# STM32WB5Mxx register map
File version: 1.0
Registers are 32-bit, read-write, reset 0x0 unless marked. A register's access mark holds for its fields unless they carry their own. Offsets are from the block's base; [hi:lo] are bit positions; {n}, {i} and the like mark numbered series.

## SYSCFG — System configuration controller
Base 0x40010000
0x00 MEMRMP — SYSCFG memory remap register
  [2:0] MEM_MODE — SYSCFG_Memory Remap Config
    0=FLASH (Main Flash memory mapped at 0x00000000); 1=SYSTEMFLASH (System Flash memory mapped at 0x00000000); 3=SRAM (SRAM1 mapped at 0x00000000); 6=QUADSPI (QUADSPI memory mapped at 0x00000000)
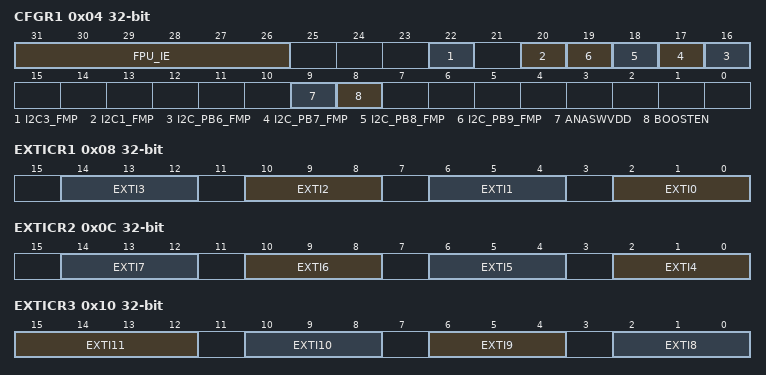
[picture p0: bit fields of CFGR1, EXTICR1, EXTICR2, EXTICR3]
0x04 CFGR1 — SYSCFG configuration register 1
  [31:26] FPU_IE — Cortex M4 Floating Point Unit interrupts enable bits
  [22] I2C3_FMP — I2C3 Fast-mode Plus (Fm+) driving capability activation
  [20] I2C1_FMP — I2C1 Fast-mode Plus (Fm+) driving capability activation
  [n+10] I2C_PB{n}_FMP (n=6..9) — Fast-mode Plus (Fm+) driving capability activation on PB{n}
  [9] ANASWVDD — I/O analog switch voltage selection
  [8] BOOSTEN — I/O analog switch voltage booster enable
0x08 EXTICR1 — SYSCFG external interrupt configuration registers
  [4n+2:4n] EXTI{n} (n=0..3) — External Interrupt Line {n} configuration
0x0C EXTICR2 — SYSCFG external interrupt configuration registers
  [4n-14:4n-16] EXTI{n} (n=4..7) — External Interrupt Line {n} configuration
0x10 EXTICR3 — SYSCFG external interrupt configuration registers
  [15:12] EXTI11 — External Interrupt Line 11 configuration
  [10:8] EXTI10 — External Interrupt Line 10 configuration
  [6:4] EXTI9 — External Interrupt Line 9 configuration
  [2:0] EXTI8 — External Interrupt Line 8 configuration
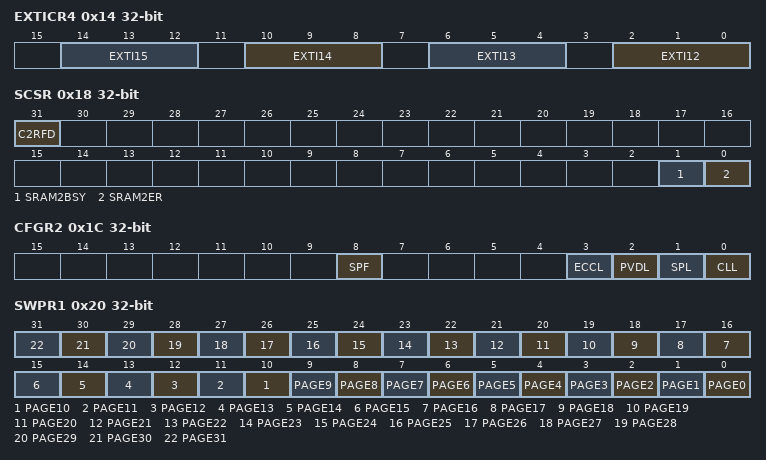
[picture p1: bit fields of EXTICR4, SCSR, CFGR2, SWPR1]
0x14 EXTICR4 — SYSCFG external interrupt configuration registers
  [4n-46:4n-48] EXTI{n} (n=12..15) — External Interrupt Line {n} configuration
0x18 SCSR — SYSCFG SRAM2 control and status register
  [31] C2RFD — CPU2 SRAM fetch (execution) disable
  [1] SRAM2BSY — SRAM2 and PKA RAM busy by erase operation
  [0] SRAM2ER — SRAM2 and PKA RAM Erase
0x1C CFGR2 — SYSCFG configuration register 2
  [8] SPF — SRAM2 Parity Lock
  [3] ECCL — ECC Lock
  [2] PVDL — PVD Lock
  [1] SPL — SRAM2 Parity Lock
  [0] CLL — Cortex M4 LOCKUP (hardfault) output enable
0x20 SWPR1 — SYSCFG SRAM2 write protection register part 1
  [n] PAGE{n} (n=0..31) — SRAM2A Write protection page {n} ({0x20030000+0x400*n} - {0x200303FF+0x400*n})
0x24 SKR — SYSCFG SRAM2 key register
  [7:0] KEY — SRAM2 write protection key for software erase
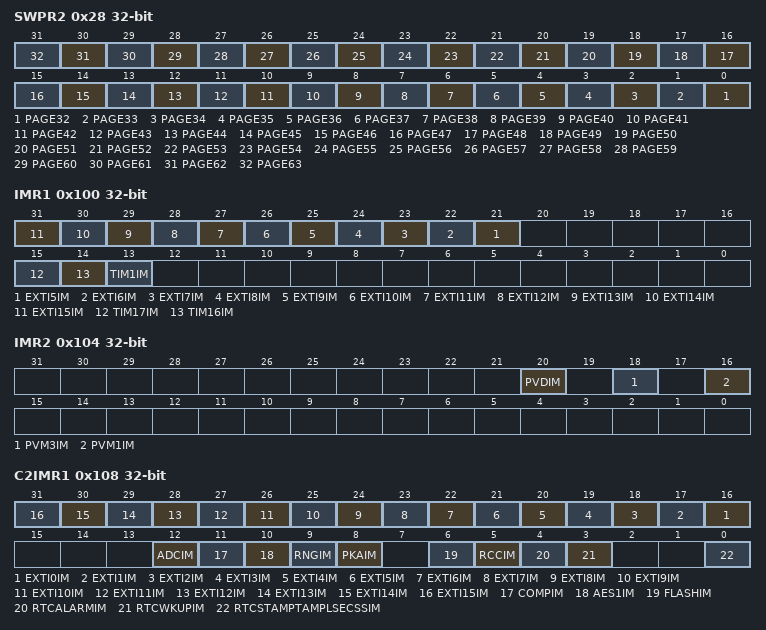
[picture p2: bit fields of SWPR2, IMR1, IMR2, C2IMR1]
0x28 SWPR2 — SYSCFG write protection register part 2
  [n-32] PAGE{n} (n=32..63) — SRAM2B Write protection page {n-32} ({0x20030000+0x400*n} - {0x200303FF+0x400*n})
0x100 IMR1 — SYSCFG CPU1 (CORTEX M4) interrupt masks control-status register part 1
  [n+16] EXTI{n}IM (n=5..15) — Enabling of interrupt from External Interrupt Line {n} to CPU1
  [15] TIM17IM — Enabling of interrupt from Timer 17 to CPU1
  [14] TIM16IM — Enabling of interrupt from Timer 16 to CPU1
  [13] TIM1IM — Enabling of interrupt from Timer 1 to CPU1
0x104 IMR2 — SYSCFG CPU1 (CORTEX M4) interrupt masks control-status register part 2
  [20] PVDIM — Enabling of interrupt from Power Voltage Detector to CPU1
  [18] PVM3IM — Enabling of interrupt from Power Voltage Monitoring 3 to CPU1
  [16] PVM1IM — Enabling of interrupt from Power Voltage Monitoring 1 to CPU1
0x108 C2IMR1 — SYSCFG CPU2 (CORTEX M0) interrupt masks control-status register part 1
  [n+16] EXTI{n}IM (n=0..15) — Enabling of interrupt from External Interrupt Line {n} to CPU2
  [12] ADCIM — Enabling of interrupt from Analog Digital Converter to CPU2
  [11] COMPIM — Enabling of interrupt from Comparator to CPU2
  [10] AES1IM — Enabling of interrupt from Advanced Encryption Standard 1 to CPU2
  [9] RNGIM — Enabling of interrupt from Random Number Generator to CPU2
  [8] PKAIM — Enabling of interrupt from Public Key Accelerator to CPU2
  [6] FLASHIM — Enabling of interrupt from FLASH to CPU2
  [5] RCCIM — Enabling of interrupt from RCC to CPU2
  [4] RTCALARMIM — Enabling of interrupt from RTC Alarms to CPU2
  [3] RTCWKUPIM — Enabling of interrupt from RTC Wakeup to CPU2
  [0] RTCSTAMPTAMPLSECSSIM
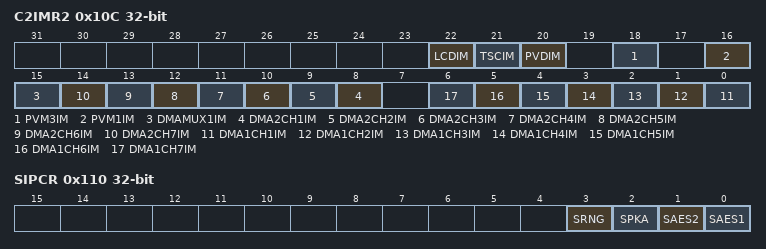
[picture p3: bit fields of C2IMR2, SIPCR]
0x10C C2IMR2 — SYSCFG CPU2 (CORTEX M0) interrupt masks control-status register part 2
  [22] LCDIM — Enabling of interrupt from Liquid Crystal Display to CPU2
  [21] TSCIM — Enabling of interrupt from Touch Sensing Controller to CPU2
  [20] PVDIM — Enabling of interrupt from Power Voltage Detector to CPU2
  [18] PVM3IM — Enabling of interrupt from Power Voltage Monitoring 3 to CPU2
  [16] PVM1IM — Enabling of interrupt from Power Voltage Monitoring 1 to CPU2
  [15] DMAMUX1IM — Enabling of interrupt from DMAMUX1 to CPU2
  [n+7] DMA2CH{n}IM (n=1..7) — Enabling of interrupt from DMA2 Channel {n} to CPU2
  [n-1] DMA1CH{n}IM (n=1..7) — Enabling of interrupt from DMA1 Channel {n} to CPU2
0x110 SIPCR — SYSCFG secure IP control register
  [3] SRNG — Enabling the security access of Random Number Generator
  [2] SPKA — Enabling the security access of Public Key Accelerator
  [1] SAES2 — Enabling the security access of Advanced Encryption Standard 2
  [0] SAES1 — Enabling the security access of Advanced Encryption Standard 1 KEY[7:0]
